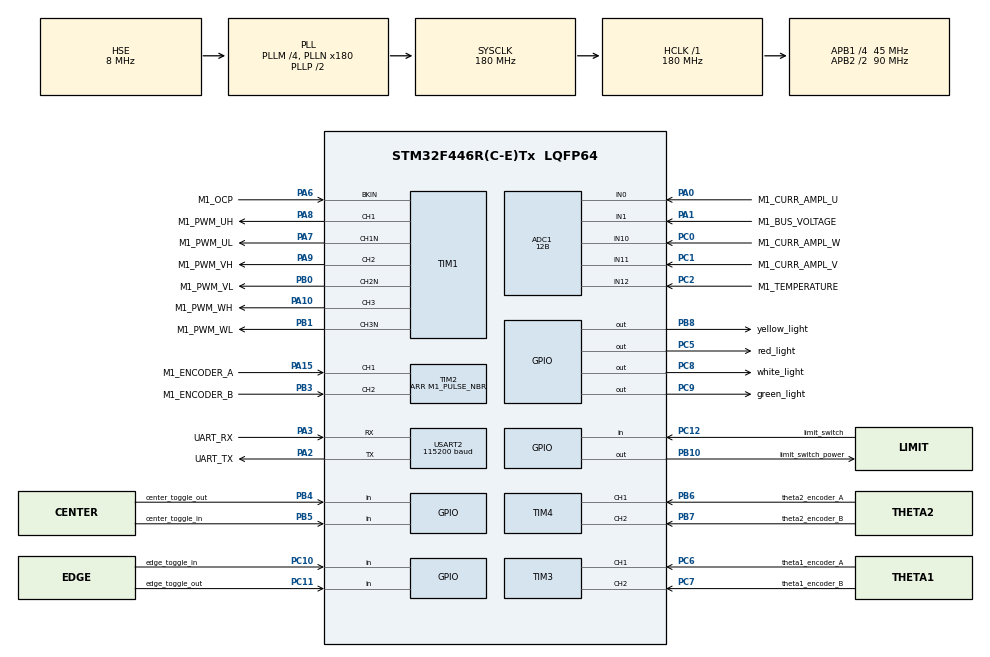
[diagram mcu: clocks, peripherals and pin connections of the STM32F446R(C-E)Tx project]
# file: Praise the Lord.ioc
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ADC1.Channel-1\#ChannelInjectedConversion=ADC_CHANNEL_0
ADC1.Channel-1\#ChannelRegularConversion=ADC_CHANNEL_1
ADC1.Channel-2\#ChannelInjectedConversion=ADC_CHANNEL_11
ADC1.Channel-2\#ChannelRegularConversion=ADC_CHANNEL_12
ADC1.Channel-3\#ChannelInjectedConversion=ADC_CHANNEL_10
ADC1.ClockPrescaler=ADC_CLOCK_SYNC_PCLK_DIV4
ADC1.ContinuousConvMode=DISABLE
ADC1.DMAContinuousRequests=DISABLE
ADC1.DataAlign=ADC_DATAALIGN_LEFT
ADC1.DiscontinuousConvMode=DISABLE
ADC1.EOCSelection=ADC_EOC_SINGLE_CONV
ADC1.EnableAnalogWatchDog=false
ADC1.EnableInjectedConversion=ENABLE
ADC1.EnableRegularConversion=ENABLE
ADC1.ExternalTrigConv=ADC_SOFTWARE_START
ADC1.ExternalTrigConvEdge=ADC_EXTERNALTRIGCONVEDGE_NONE
ADC1.ExternalTrigInjecConv=ADC_EXTERNALTRIGINJECCONV_T1_CC4
ADC1.ExternalTrigInjecConvEdge=ADC_EXTERNALTRIGINJECCONVEDGE_RISING
ADC1.InjNumberOfConversion=3
ADC1.InjectedConvMode=None
ADC1.InjectedOffset-1\#ChannelInjectedConversion=0
ADC1.InjectedOffset-2\#ChannelInjectedConversion=0
ADC1.InjectedOffset-3\#ChannelInjectedConversion=0
ADC1.InjectedRank-1\#ChannelInjectedConversion=1
ADC1.InjectedRank-2\#ChannelInjectedConversion=2
ADC1.InjectedRank-3\#ChannelInjectedConversion=3
ADC1.NbrOfConversion=2
ADC1.NbrOfConversionFlag=1
ADC1.Offset-1\#ChannelRegularConversion=0
ADC1.Offset-2\#ChannelRegularConversion=0
ADC1.OffsetNumber-1\#ChannelRegularConversion=ADC_OFFSET_NONE
ADC1.OffsetNumber-2\#ChannelRegularConversion=ADC_OFFSET_NONE
ADC1.Rank-1\#ChannelRegularConversion=1
ADC1.Rank-2\#ChannelRegularConversion=2
ADC1.Resolution=ADC_RESOLUTION_12B
ADC1.SamplingTime-1\#ChannelInjectedConversion=ADC_SAMPLETIME_15CYCLES
ADC1.SamplingTime-1\#ChannelRegularConversion=ADC_SAMPLETIME_28CYCLES
ADC1.SamplingTime-2\#ChannelInjectedConversion=ADC_SAMPLETIME_15CYCLES
ADC1.SamplingTime-2\#ChannelRegularConversion=ADC_SAMPLETIME_28CYCLES
ADC1.SamplingTime-3\#ChannelInjectedConversion=ADC_SAMPLETIME_15CYCLES
ADC1.ScanConvMode=ENABLE
ADC1.master=1
Dma.Request0=USART2_RX
Dma.Request1=USART2_TX
Dma.USART2_RX.0.Direction=DMA_PERIPH_TO_MEMORY
Dma.USART2_RX.0.FIFOMode=DMA_FIFOMODE_DISABLE
Dma.USART2_RX.0.Instance=DMA1_Stream5
Dma.USART2_RX.0.MemDataAlignment=DMA_MDATAALIGN_BYTE
Dma.USART2_RX.0.MemInc=DMA_MINC_ENABLE
Dma.USART2_RX.0.Mode=DMA_NORMAL
Dma.USART2_RX.0.PeriphDataAlignment=DMA_PDATAALIGN_BYTE
Dma.USART2_RX.0.PeriphInc=DMA_PINC_DISABLE
Dma.USART2_RX.0.Priority=DMA_PRIORITY_LOW
Dma.USART2_TX.1.Direction=DMA_MEMORY_TO_PERIPH
Dma.USART2_TX.1.FIFOMode=DMA_FIFOMODE_DISABLE
Dma.USART2_TX.1.Instance=DMA1_Stream6
Dma.USART2_TX.1.MemDataAlignment=DMA_MDATAALIGN_BYTE
Dma.USART2_TX.1.MemInc=DMA_MINC_ENABLE
Dma.USART2_TX.1.Mode=DMA_NORMAL
Dma.USART2_TX.1.PeriphDataAlignment=DMA_PDATAALIGN_BYTE
Dma.USART2_TX.1.PeriphInc=DMA_PINC_DISABLE
Dma.USART2_TX.1.Priority=DMA_PRIORITY_LOW
ExtraMW=MotorControl
ExtraMW.MotorControl.Config=MotorControl
ExtraMW.MotorControl.Mode=MotorControl
ExtraMW.MotorControl.Root=MCSDK_v6.3.2-Full/MotorControl
ExtraMW.MotorControl.Template=templates
Mcu.Family=STM32F4
Mcu.Name=STM32F446R(C-E)Tx
Mcu.Package=LQFP64
MotorControl.ADC_AHBPERIPH=RCC_AHBPeriph_ADC1
MotorControl.ADC_CLOCK_WB_DIV=1
MotorControl.ADC_PERIPH=ADC1
MotorControl.ADC_REFERENCE_VOLTAGE=3.3
MotorControl.BOARD=NUCLEO-F446RE
MotorControl.BUS_VOLTAGE_READING=true
MotorControl.CCMRAM_ENABLED=false
MotorControl.CLOCK_FREQUENCY=CPU_CLK_180_MHZ
MotorControl.CLOCK_SOURCE=EXTERNAL
MotorControl.CPU_CLK_180_MHZ=true
MotorControl.CTLBOARD_NAME=NUCLEO-F446RE
MotorControl.CUBE_MX_VER=6.13.0
MotorControl.CURRENT_READING_TOPOLOGY=THREE_SHUNT
MotorControl.CURR_SAMPLING_TIME=15
MotorControl.DBG_MCU_LOAD_MEASURE=false
MotorControl.DEBUG_DAC_FUNCTIONALITY_EN=false
MotorControl.DRIVES_NUMBER_SELECTION=SINGLEDRIVE
MotorControl.DRIVE_NUMBER=1
MotorControl.DRIVE_TYPE=FOC
MotorControl.EMERGENCY_STOP_GPIO_PIN=LL_GPIO_PIN_6
MotorControl.EMERGENCY_STOP_GPIO_PORT=GPIOA
MotorControl.ENCODER=true
MotorControl.ENCODER_AVAILABLE=true
MotorControl.ENCODER_PPR=2048
MotorControl.ENC_A_GPIO_PIN=LL_GPIO_PIN_15
MotorControl.ENC_A_GPIO_PORT=GPIOA
MotorControl.ENC_B_GPIO_PIN=LL_GPIO_PIN_3
MotorControl.ENC_B_GPIO_PORT=GPIOB
MotorControl.ENC_ICx_FILTER=126
MotorControl.ENC_INVERT_SPEED=false
MotorControl.ENC_TIMER_SELECTION=ENC_TIM2
MotorControl.ENC_USE_CH3=false
MotorControl.EXT_CLK_8_MHZ=true
MotorControl.EXT_CLOCK_FREQUENCY=EXT_CLK_8_MHZ
MotorControl.FEEDBACK_NET_FILTERING=false
MotorControl.FLASH_SIZE=512
MotorControl.HALL_SENSORS_AVAILABLE=false
MotorControl.HIGH_SIDE_IDLE_STATE=false
MotorControl.HWV_CS=ThreeShunt_AmplifiedCurrents
MotorControl.HWV_OCP=OnPowerStageOCP
MotorControl.HWV_PWM=DrivingHighAndLowSides
MotorControl.HW_COMPLEMENTED_LOW_SIDE=false
MotorControl.HW_DEAD_TIME_NS=1000
MotorControl.IPs=NVIC,RCC,SYS,MotorControl,ADC1,TIM1,TIM2,USART2,DMA
MotorControl.LOW_MEMORY_FOOTPRINT_REG=false
MotorControl.LOW_SIDE_IDLE_STATE=false
MotorControl.LOW_SIDE_SIGNALS_ENABLING=LS_PWM_TIMER
MotorControl.M1_ALIGNMENT_ANGLE_DEG=90
MotorControl.M1_ALIGNMENT_DURATION=700
MotorControl.M1_AMPLIFICATION_GAIN=5.18
MotorControl.M1_ANGC={0,0,0,0,0,0,0,0}
MotorControl.M1_AUXILIARY_SPEED_SENSOR=NONE
MotorControl.M1_BOARD_MAX_CURRENT=19
MotorControl.M1_BUS_VOLTAGE_READING=true
MotorControl.M1_COMMUTATION_STEP_TIME_BUF_SIZE=12
MotorControl.M1_CONSTANT1_D=21764
MotorControl.M1_CONSTANT1_Q=21764
MotorControl.M1_CONSTANT2_QD=57888
MotorControl.M1_CS_ADC_NUM=1
MotorControl.M1_CS_ADC_PHASE_SHARED=NONE
MotorControl.M1_CS_ADC_U=ADC1
MotorControl.M1_CS_ADC_V=ADC1
MotorControl.M1_CS_ADC_W=ADC1
MotorControl.M1_CS_CHANNEL_U=0
MotorControl.M1_CS_CHANNEL_V=11
MotorControl.M1_CS_CHANNEL_W=10
MotorControl.M1_CURRENT_AMPLIFICATION_TOPO=EXTERNAL
MotorControl.M1_CURRENT_SENSING_TOPO=THREE_SHUNT
MotorControl.M1_CURR_SAMPLING_TIME=15
MotorControl.M1_DBG_OPEN_LOOP_ENABLE=false
MotorControl.M1_DC_CURRENT_RS_MEAS=19
MotorControl.M1_DEFAULT_CONTROL_MODE=STC_TORQUE_MODE
MotorControl.M1_DEFAULT_FLUX_COMPONENT=0
MotorControl.M1_DEFAULT_TARGET_SPEED_RPM=2340
MotorControl.M1_DEFAULT_TORQUE_COMPONENT=0.0001
MotorControl.M1_DISCONTINUOUS_PWM=false
MotorControl.M1_DP_TOPOLOGY=NONE
MotorControl.M1_DRIVE_TYPE=FOC
MotorControl.M1_ENCODER_PPR=2048
MotorControl.M1_ENC_AVERAGING_FIFO_DEPTH=16
MotorControl.M1_ENC_A_GPIO_PIN=LL_GPIO_PIN_15
MotorControl.M1_ENC_A_GPIO_PORT=GPIOA
MotorControl.M1_ENC_B_GPIO_PIN=LL_GPIO_PIN_3
MotorControl.M1_ENC_B_GPIO_PORT=GPIOB
MotorControl.M1_ENC_ICx_FILTER=126
MotorControl.M1_ENC_TIMER_IRQ=TIM2
MotorControl.M1_ENC_TIMER_SELECTION=ENC_TIM2
MotorControl.M1_ENC_USE_CH3=false
MotorControl.M1_FEED_FORWARD_CURRENT_REG_ENABLING=false
MotorControl.M1_FINAL_I_ALIGNMENT=19
MotorControl.M1_FLUX_WEAKENING_ENABLING=false
MotorControl.M1_FW_KIDIV=32768
MotorControl.M1_FW_KI_GAIN=5000
MotorControl.M1_FW_KPDIV=32768
MotorControl.M1_FW_KP_GAIN=3000
MotorControl.M1_FW_VOLTAGE_REF=985
MotorControl.M1_HALL_PHASE_SHIFT=300
MotorControl.M1_HALL_SENSORS_PLACEMENT=DEGREES_120
MotorControl.M1_HIGH_SIDE_IDLE_STATE=false
MotorControl.M1_HW_DEAD_TIME_NS=1000
MotorControl.M1_ICL_ENABLED=false
MotorControl.M1_ID_DEMAG=-19
MotorControl.M1_IQMAX=19
MotorControl.M1_LDLQ_RATIO=1.000
MotorControl.M1_LOW_SIDE_IDLE_STATE=false
MotorControl.M1_LOW_SIDE_SIGNALS_ENABLING=LS_PWM_TIMER
MotorControl.M1_LS=0.000021
MotorControl.M1_MAX_APPLICATION_SPEED=6500
MotorControl.M1_MAX_MODULATION_INDEX=97
MotorControl.M1_MIN_APPLICATION_SPEED=0
MotorControl.M1_MOTOR_MAX_SPEED_RPM=6500
MotorControl.M1_MOTOR_NAME=Jay's Motor
MotorControl.M1_MOTOR_RATED_FLUX=0.089406376
MotorControl.M1_MOTOR_VOLTAGE_CONSTANT=7.3
MotorControl.M1_MTPA_ENABLING=false
MotorControl.M1_NOMINAL_BUS_VOLTAGE_V=48
MotorControl.M1_NOMINAL_CURRENT=19
MotorControl.M1_OCP_BKIN_FILTER=3
MotorControl.M1_OCP_BKIN_MODE=EXT_MODE
MotorControl.M1_OCP_BKIN_POLARITY=EMSTOP_ACTIVE_LOW
MotorControl.M1_OCP_DESTINATION=TIM_BKIN
MotorControl.M1_OCP_TOPOLOGY=EXTERNAL
MotorControl.M1_OFST={0,0,0,0,0,0,0,0}
MotorControl.M1_ON_OVER_VOLTAGE=TURN_OFF_PWM
MotorControl.M1_OVERMODULATION=false
MotorControl.M1_OVP_THRESHOLD_HIGH=48
MotorControl.M1_OV_TEMPERATURE_HYSTERESIS_C=10
MotorControl.M1_OV_TEMPERATURE_PROT_ENABLING=true
MotorControl.M1_OV_TEMPERATURE_THRESHOLD_C=90
MotorControl.M1_OV_VOLTAGE_PROT_ENABLING=true
MotorControl.M1_OV_VOLTAGE_THRESHOLD_V=48
MotorControl.M1_PID_FLUX_KD_DEFAULT=100
MotorControl.M1_PID_FLUX_KI_DEFAULT=2022
MotorControl.M1_PID_FLUX_KP_DEFAULT=2739
MotorControl.M1_PID_SPEED_KD_DEFAULT=0
MotorControl.M1_PID_SPEED_KI_DEFAULT=292
MotorControl.M1_PID_SPEED_KP_DEFAULT=3257
MotorControl.M1_PID_TORQUE_KD_DEFAULT=100
MotorControl.M1_PID_TORQUE_KI_DEFAULT=2022
MotorControl.M1_PID_TORQUE_KP_DEFAULT=2739
MotorControl.M1_POLE_PAIR_NUM=4
MotorControl.M1_POSITION_CTRL_ENABLING=false
MotorControl.M1_POTENTIOMETER_ENABLE=false
MotorControl.M1_POWERBOARD_NAME=X-NUCLEO-IHM08M1
MotorControl.M1_PWM_CHARGE_BOOT_CAP_DUTY_CYCLES=0.000
MotorControl.M1_PWM_CHARGE_BOOT_CAP_MS=10
MotorControl.M1_PWM_DRIVER_PN=L6398
MotorControl.M1_PWM_FREQUENCY=20000
MotorControl.M1_PWM_TIMER_BRK_IRQ=TIM1_BRK_TIM9
MotorControl.M1_PWM_TIMER_SELECTION=PWM_TIM1
MotorControl.M1_PWM_TIMER_UP_IRQ=TIM1_UP_TIM10
MotorControl.M1_REGULATION_EXECUTION_RATE=1
MotorControl.M1_RS=0.31
MotorControl.M1_RSHUNT=0.01
MotorControl.M1_SEGDIV=0
MotorControl.M1_SHARED_SIGNAL_ENABLE=false
MotorControl.M1_SPD_DIFFERENTIAL_TERM_ENABLING=false
MotorControl.M1_SPEED_LOOP_FREQUENCY_HZ=1000
MotorControl.M1_SPEED_SENSOR=QUAD_ENCODER
MotorControl.M1_SP_KDDIV=16
MotorControl.M1_SP_KIDIV=16384
MotorControl.M1_SP_KPDIV=512
MotorControl.M1_SS_MEAS_ERRORS_BEFORE_FAULTS=3
MotorControl.M1_SW_DEADTIME_NS=850
MotorControl.M1_T0_C=25
MotorControl.M1_TEMPERATURE_READING=true
MotorControl.M1_TEMP_ADC_SAMPLING_TIME=28
MotorControl.M1_TEMP_FDBK_ADC=ADC1
MotorControl.M1_TEMP_FDBK_CHANNEL=ADC_CHANNEL_12
MotorControl.M1_TF_KDDIV=8192
MotorControl.M1_TF_KIDIV=16384
MotorControl.M1_TF_KPDIV=16384
MotorControl.M1_TNOISE_NS=1000
MotorControl.M1_TRISE_NS=1000
MotorControl.M1_T_MAX=110
MotorControl.M1_UD_VOLTAGE_THRESHOLD_V=10
MotorControl.M1_USE_INTERNAL_OPAMP=false
MotorControl.M1_UV_VOLTAGE_PROT_ENABLING=true
MotorControl.M1_V0_V=1.055
MotorControl.M1_VBUS_ADC=ADC1
MotorControl.M1_VBUS_ADC_SAMPLING_TIME=28
MotorControl.M1_VBUS_CHANNEL=ADC_CHANNEL_1
MotorControl.M1_VBUS_PARTITIONING_FACTOR=0.052164840897235255
MotorControl.M1_dV_dT=0.023
MotorControl.MAX_READABLE_CURRENT=31.845
MotorControl.MCPA_OVER_UART_A_STREAM=10
MotorControl.MCP_ASPEP_OVER_UART=true
MotorControl.MCP_ASYNC_EN=true
MotorControl.MCP_ASYNC_OVER_ASPEP_EN=true
MotorControl.MCP_ASYNC_OVER_UART_A_EN=true
MotorControl.MCP_DMACH_RX_UART_A=5
MotorControl.MCP_DMACH_TX_UART_A=6
MotorControl.MCP_DMA_RX_UART_A=DMA1
MotorControl.MCP_DMA_TX_UART_A=DMA1
MotorControl.MCP_EN=true
MotorControl.MCP_IRQ_HANDLER_DMA_RX_UART_A=DMA1_Stream5_IRQHandler
MotorControl.MCP_IRQ_HANDLER_UART_A=USART2_IRQHandler
MotorControl.MCP_OVER_ASPEP_EN=true
MotorControl.MCP_OVER_STLNK_EN=false
MotorControl.MCP_OVER_UART_A_EN=true
MotorControl.MCP_OVER_UART_B_EN=false
MotorControl.MCP_RX_SYNC_PAYLOAD_MAX=128
MotorControl.MCP_TX_ASYNC_PAYLOAD_MAX_UART_A=2048
MotorControl.MCP_TX_SYNC_PAYLOAD_MAX=128
MotorControl.MCU=STM32F446RE
MotorControl.MCU_FAMILY=STM32F4
MotorControl.MCU_LINE=STM32F446
MotorControl.MCU_NAME=STM32F446R(C-E)Tx
MotorControl.MCU_PACKAGE=LQFP64
MotorControl.MCU_TYPE=STM32F446RE
MotorControl.MCU_USERNAME=STM32F446RETx
MotorControl.MC_WORKBENCH_VERSION=6.3.2
MotorControl.MOTOR_PROFILER=false
MotorControl.MOTOR_TYPE=PMSM
MotorControl.ON_OVER_VOLTAGE=TURN_OFF_PWM
MotorControl.OV_TEMPERATURE_PROT_ENABLING=true
MotorControl.OV_VOLTAGE_PROT_ENABLING=true
MotorControl.PHASE_UH_GPIO_PIN=LL_GPIO_PIN_8
MotorControl.PHASE_UH_GPIO_PORT=GPIOA
MotorControl.PHASE_UH_POLARITY=H_ACTIVE_HIGH
MotorControl.PHASE_UL_GPIO_PIN=LL_GPIO_PIN_7
MotorControl.PHASE_UL_GPIO_PORT=GPIOA
MotorControl.PHASE_UL_POLARITY=L_ACTIVE_LOW
MotorControl.PHASE_U_CURR_ADC=ADC1
MotorControl.PHASE_U_CURR_CHANNEL=ADC_CHANNEL_0
MotorControl.PHASE_U_GPIO_PIN=LL_GPIO_PIN_0
MotorControl.PHASE_U_GPIO_PORT=GPIOA
MotorControl.PHASE_U_PWM_CHANNEL=TIM_Channel_1
MotorControl.PHASE_VH_GPIO_PIN=LL_GPIO_PIN_9
MotorControl.PHASE_VH_GPIO_PORT=GPIOA
MotorControl.PHASE_VH_POLARITY=H_ACTIVE_HIGH
MotorControl.PHASE_VL_GPIO_PIN=LL_GPIO_PIN_0
MotorControl.PHASE_VL_GPIO_PORT=GPIOB
MotorControl.PHASE_VL_POLARITY=L_ACTIVE_LOW
MotorControl.PHASE_V_CURR_ADC=ADC1
MotorControl.PHASE_V_CURR_CHANNEL=ADC_CHANNEL_11
MotorControl.PHASE_V_GPIO_PIN=LL_GPIO_PIN_1
MotorControl.PHASE_V_GPIO_PORT=GPIOC
MotorControl.PHASE_V_PWM_CHANNEL=TIM_Channel_2
MotorControl.PHASE_WH_GPIO_PIN=LL_GPIO_PIN_10
MotorControl.PHASE_WH_GPIO_PORT=GPIOA
MotorControl.PHASE_WH_POLARITY=H_ACTIVE_HIGH
MotorControl.PHASE_WL_GPIO_PIN=LL_GPIO_PIN_1
MotorControl.PHASE_WL_GPIO_PORT=GPIOB
MotorControl.PHASE_WL_POLARITY=L_ACTIVE_LOW
MotorControl.PHASE_W_CURR_ADC=ADC1
MotorControl.PHASE_W_CURR_CHANNEL=ADC_CHANNEL_10
MotorControl.PHASE_W_GPIO_PIN=LL_GPIO_PIN_0
MotorControl.PHASE_W_GPIO_PORT=GPIOC
MotorControl.PHASE_W_PWM_CHANNEL=TIM_Channel_3
MotorControl.POTENTIOMETER_READING=false
MotorControl.PWM_FREQUENCY=20000
MotorControl.PWM_TIMER_SELECTION=PWM_TIM1
MotorControl.REGULATION_EXECUTION_RATE=1
MotorControl.RTOS=NONE
MotorControl.R_BRAKE_SWITCH_OFF_THRES_V=38
MotorControl.SINGLEDRIVE=true
MotorControl.SPD_DIFFERENTIAL_TERM_ENABLING=false
MotorControl.SPEED_SENSOR_SELECTION=ENCODER
MotorControl.START_STOP_BTN=false
MotorControl.STM32F446RE=true
MotorControl.SW_DEADTIME_NS=850
MotorControl.TEMPERATURE_READING=true
MotorControl.TEMP_ADC_SAMPLING_TIME=28
MotorControl.TEMP_FDBK_ADC=ADC1
MotorControl.TEMP_FDBK_CHANNEL=ADC_CHANNEL_12
MotorControl.TEMP_FDBK_GPIO_PIN=LL_GPIO_PIN_2
MotorControl.TEMP_FDBK_GPIO_PORT=GPIOC
MotorControl.TFDIFFERENTIAL_TERM_ENABLING=false
MotorControl.THREE_SHUNT=true
MotorControl.TRISE_NS=1000
MotorControl.USART_RX_GPIO_PIN=LL_GPIO_PIN_3
MotorControl.USART_RX_GPIO_PORT=GPIOA
MotorControl.USART_SELECTION=USE_USART2
MotorControl.USART_SELECTION_A=USART2
MotorControl.USART_SPEED=115200
MotorControl.USART_TX_GPIO_PIN=LL_GPIO_PIN_2
MotorControl.USART_TX_GPIO_PORT=GPIOA
MotorControl.USE_3OPAMPS=false
MotorControl.USE_INTERNAL_OPAMP=false
MotorControl.UV_VOLTAGE_PROT_ENABLING=true
MotorControl.VBUS_ADC=ADC1
MotorControl.VBUS_ADC_SAMPLING_TIME=28
MotorControl.VBUS_CHANNEL=ADC_CHANNEL_1
MotorControl.VBUS_GPIO_PIN=LL_GPIO_PIN_1
MotorControl.VBUS_GPIO_PORT=GPIOA
MotorControl.WB_UI_CUTOFF_FREQUENCY=6000
MotorControl.WB_UI_ENCODER_HAS_INDEX_PIN=false
MotorControl.WB_UI_FLUX_TARGET=0
MotorControl.WB_UI_FRICTION=14
MotorControl.WB_UI_INERTIA=5
MotorControl.WB_UI_MAGNETIC_STRUCTURE=SM-PMSM
MotorControl.WB_UI_MAX_CURRENT=19
MotorControl.WB_UI_MAX_NOMINAL_DC_VOLTAGE=48
MotorControl.WB_UI_MAX_PWMFREQUENCY=100000
MotorControl.WB_UI_MOTOR_DESCRIPTION=brushless DC motor with encoder and Z Index
MotorControl.WB_UI_OCP_DISABLING_ENABLE=false
MotorControl.WB_UI_OCP_THRESHOLD=30
MotorControl.WB_UI_PW_BOARD_MAX_RATED_CURRENT=30
MotorControl.WB_UI_PW_BOARD_MAX_VOLTAGE=48
MotorControl.WB_UI_PW_BOARD_MIN_VOLTAGE=10
MotorControl.WB_UI_VPOL=1.71
MotorControl.WB_to_Mx_template_version=24-04-17
MotorControl.WB_to_Mx_version=6.2.3
NVIC.ADC_IRQn=true\:2\:0\:true\:true\:false\:3\:false\:true\:true
NVIC.DMA1_Stream5_IRQn=true\:3\:0\:true\:true\:false\:2\:true\:true\:true
NVIC.PriorityGroup=NVIC_PRIORITYGROUP_3
NVIC.TIM1_BRK_TIM9_IRQn=true\:4\:1\:false\:true\:false\:5\:true\:true\:true
NVIC.TIM1_TRG_COM_TIM11_IRQn=true\:0\:0\:false\:false\:true\:true\:true\:true
NVIC.TIM1_UP_TIM10_IRQn=true\:0\:0\:false\:true\:false\:4\:true\:true\:true
NVIC.TIM2_IRQn=true\:3\:0\:false\:true\:false\:6\:true\:true\:true
NVIC.TIM8_TRG_COM_TIM14_IRQn=true\:0\:0\:false\:false\:true\:true\:true\:true
NVIC.TIM8_UP_TIM13_IRQn=true\:0\:0\:false\:false\:true\:true\:true\:true
NVIC.USART2_IRQn=true\:3\:1\:true\:true\:false\:1\:true\:true\:true
PA0-WKUP.GPIO_Label=M1_CURR_AMPL_U
PA0-WKUP.Signal=ADCx_IN0
PA1.GPIO_Label=M1_BUS_VOLTAGE
PA1.Signal=ADCx_IN1
PA10.GPIO_Label=M1_PWM_WH
PA10.GPIO_PuPd=GPIO_PULLDOWN
PA10.GPIO_Speed=GPIO_SPEED_FREQ_HIGH
PA10.Signal=S_TIM1_CH3
PA15.GPIO_Label=M1_ENCODER_A
PA15.Signal=S_TIM2_CH1_ETR
PA2.GPIO_Label=UART_TX
PA2.GPIO_Mode=GPIO_MODE_AF_PP
PA2.GPIO_PuPd=GPIO_NOPULL
PA2.GPIO_Speed=GPIO_SPEED_FREQ_LOW
PA2.Mode=Asynchronous
PA2.Signal=USART2_TX
PA3.GPIO_Label=UART_RX
PA3.GPIO_Mode=GPIO_MODE_AF_PP
PA3.GPIO_PuPd=GPIO_NOPULL
PA3.GPIO_Speed=GPIO_SPEED_FREQ_LOW
PA3.Mode=Asynchronous
PA3.Signal=USART2_RX
PA6.GPIO_Label=M1_OCP
PA6.GPIO_PuPd=GPIO_PULLUP
PA6.Mode=Activate-Break-Input
PA6.Signal=TIM1_BKIN
PA7.GPIO_Label=M1_PWM_UL
PA7.GPIO_PuPd=GPIO_PULLUP
PA7.GPIO_Speed=GPIO_SPEED_FREQ_HIGH
PA7.Mode=PWM Generation1 CH1 CH1N
PA7.Signal=TIM1_CH1N
PA8.GPIO_Label=M1_PWM_UH
PA8.GPIO_PuPd=GPIO_PULLDOWN
PA8.GPIO_Speed=GPIO_SPEED_FREQ_HIGH
PA8.Signal=S_TIM1_CH1
PA9.GPIO_Label=M1_PWM_VH
PA9.GPIO_PuPd=GPIO_PULLDOWN
PA9.GPIO_Speed=GPIO_SPEED_FREQ_HIGH
PA9.Signal=S_TIM1_CH2
PB0.GPIO_Label=M1_PWM_VL
PB0.GPIO_PuPd=GPIO_PULLUP
PB0.GPIO_Speed=GPIO_SPEED_FREQ_HIGH
PB0.Mode=PWM Generation2 CH2 CH2N
PB0.Signal=TIM1_CH2N
PB1.GPIO_Label=M1_PWM_WL
PB1.GPIO_PuPd=GPIO_PULLUP
PB1.GPIO_Speed=GPIO_SPEED_FREQ_HIGH
PB1.Mode=PWM Generation3 CH3 CH3N
PB1.Signal=TIM1_CH3N
PB10.GPIO_Label=limit_switch_power
PB10.GPIO_ModeDefaultOutputPP=GPIO_MODE_OUTPUT_PP
PB10.GPIO_Speed=GPIO_SPEED_FREQ_VERY_HIGH
PB10.PinState=GPIO_PIN_SET
PB10.Signal=GPIO_Output
PB3.GPIO_Label=M1_ENCODER_B
PB3.Signal=S_TIM2_CH2
PB4.GPIO_Label=center_toggle_out
PB4.GPIO_PuPd=GPIO_PULLDOWN
PB4.Signal=GPIO_Input
PB5.GPIO_Label=center_toggle_in
PB5.GPIO_PuPd=GPIO_PULLDOWN
PB5.Signal=GPIO_Input
PB6.GPIO_Label=theta2_encoder_A
PB6.Signal=S_TIM4_CH1
PB7.GPIO_Label=theta2_encoder_B
PB7.Signal=S_TIM4_CH2
PB8.GPIO_Label=yellow_light
PB8.PinState=GPIO_PIN_SET
PB8.Signal=GPIO_Output
PC0.GPIO_Label=M1_CURR_AMPL_W
PC0.Signal=ADCx_IN10
PC1.GPIO_Label=M1_CURR_AMPL_V
PC1.Signal=ADCx_IN11
PC10.GPIO_Label=edge_toggle_in
PC10.GPIO_PuPd=GPIO_PULLDOWN
PC10.Signal=GPIO_Input
PC11.GPIO_Label=edge_toggle_out
PC11.GPIO_PuPd=GPIO_PULLDOWN
PC11.Signal=GPIO_Input
PC12.GPIO_Label=limit_switch
PC12.GPIO_PuPd=GPIO_PULLDOWN
PC12.Signal=GPIO_Input
PC2.GPIO_Label=M1_TEMPERATURE
PC2.Signal=ADCx_IN12
PC5.GPIO_Label=red_light
PC5.PinState=GPIO_PIN_SET
PC5.Signal=GPIO_Output
PC6.GPIO_Label=theta1_encoder_A
PC6.Signal=S_TIM3_CH1
PC7.GPIO_Label=theta1_encoder_B
PC7.Signal=S_TIM3_CH2
PC8.GPIO_Label=white_light
PC8.PinState=GPIO_PIN_SET
PC8.Signal=GPIO_Output
PC9.GPIO_Label=green_light
PC9.PinState=GPIO_PIN_SET
PC9.Signal=GPIO_Output
PH0-OSC_IN.Mode=HSE-External-Oscillator
PH0-OSC_IN.Signal=RCC_OSC_IN
PH1-OSC_OUT.Mode=HSE-External-Oscillator
PH1-OSC_OUT.Signal=RCC_OSC_OUT
ProjectManager.HeapSize=0x200
ProjectManager.StackSize=0x400
ProjectManager.TargetToolchain=STM32CubeIDE
RCC.AHBFreq_Value=180000000
RCC.APB1CLKDivider=RCC_HCLK_DIV4
RCC.APB1Freq_Value=45000000
RCC.APB1TimFreq_Value=90000000
RCC.APB2CLKDivider=RCC_HCLK_DIV2
RCC.APB2Freq_Value=90000000
RCC.APB2TimFreq_Value=180000000
RCC.CortexFreq_Value=180000000
RCC.HCLKFreq_Value=180000000
RCC.HSE_VALUE=8000000
RCC.PLLM=4
RCC.PLLN=180
RCC.PLLSourceVirtual=RCC_PLLSOURCE_HSE
RCC.PREFETCH_ENABLE=1
RCC.SYSCLKFreq_VALUE=180000000
RCC.SYSCLKSource=RCC_SYSCLKSOURCE_PLLCLK
RCC.USBFreq_Value=180000000
RCC.VCOOutputFreq_Value=360000000
SH.ADCx_IN0.0=ADC1_IN0,IN0
SH.ADCx_IN1.0=ADC1_IN1,IN1
SH.ADCx_IN10.0=ADC1_IN10,IN10
SH.ADCx_IN11.0=ADC1_IN11,IN11
SH.ADCx_IN12.0=ADC1_IN12,IN12
SH.S_TIM1_CH1.0=TIM1_CH1,PWM Generation1 CH1 CH1N
SH.S_TIM1_CH2.0=TIM1_CH2,PWM Generation2 CH2 CH2N
SH.S_TIM1_CH3.0=TIM1_CH3,PWM Generation3 CH3 CH3N
SH.S_TIM2_CH1_ETR.0=TIM2_CH1,Encoder_Interface
SH.S_TIM2_CH2.0=TIM2_CH2,Encoder_Interface
SH.S_TIM3_CH1.0=TIM3_CH1,Encoder_Interface
SH.S_TIM3_CH2.0=TIM3_CH2,Encoder_Interface
SH.S_TIM4_CH1.0=TIM4_CH1,Encoder_Interface
SH.S_TIM4_CH2.0=TIM4_CH2,Encoder_Interface
TIM1.AutoReloadPreload=TIM_AUTORELOAD_PRELOAD_DISABLE
TIM1.AutomaticOutput=TIM_AUTOMATICOUTPUT_DISABLE
TIM1.BreakPolarity=TIM_BREAKPOLARITY_LOW
TIM1.BreakState=TIM_BREAK_ENABLE
TIM1.Channel-PWM\ Generation1\ CH1\ CH1N=TIM_CHANNEL_1
TIM1.Channel-PWM\ Generation2\ CH2\ CH2N=TIM_CHANNEL_2
TIM1.Channel-PWM\ Generation3\ CH3\ CH3N=TIM_CHANNEL_3
TIM1.Channel-PWM\ Generation4\ No\ Output=TIM_CHANNEL_4
TIM1.ClearInputSource=TIM_CLEARINPUTSOURCE_NONE
TIM1.ClockDivision=TIM_CLOCKDIVISION_DIV2
TIM1.CounterMode=TIM_COUNTERMODE_CENTERALIGNED1
TIM1.DeadTime=((DEAD_TIME_COUNTS) / 2)
TIM1.LockLevel=TIM_LOCKLEVEL_OFF
TIM1.OC1Preload_PWM=ENABLE
TIM1.OC2Preload_PWM=ENABLE
TIM1.OC3Preload_PWM=ENABLE
TIM1.OC4Preload_PWM=ENABLE
TIM1.OCIdleState_1=TIM_OCIDLESTATE_RESET
TIM1.OCIdleState_2=TIM_OCIDLESTATE_RESET
TIM1.OCIdleState_3=TIM_OCIDLESTATE_RESET
TIM1.OCIdleState_4=TIM_OCIDLESTATE_RESET
TIM1.OCMode_PWM-PWM\ Generation1\ CH1\ CH1N=TIM_OCMODE_PWM1
TIM1.OCMode_PWM-PWM\ Generation2\ CH2\ CH2N=TIM_OCMODE_PWM1
TIM1.OCMode_PWM-PWM\ Generation3\ CH3\ CH3N=TIM_OCMODE_PWM1
TIM1.OCMode_PWM-PWM\ Generation4\ No\ Output=TIM_OCMODE_PWM2
TIM1.OCNIdleState_1=TIM_OCNIDLESTATE_SET
TIM1.OCNIdleState_2=TIM_OCNIDLESTATE_SET
TIM1.OCNIdleState_3=TIM_OCNIDLESTATE_SET
TIM1.OCNPolarity_1=TIM_OCNPOLARITY_LOW
TIM1.OCNPolarity_2=TIM_OCNPOLARITY_LOW
TIM1.OCNPolarity_3=TIM_OCNPOLARITY_LOW
TIM1.OCPolarity_1=TIM_OCPOLARITY_HIGH
TIM1.OCPolarity_2=TIM_OCPOLARITY_HIGH
TIM1.OCPolarity_3=TIM_OCPOLARITY_HIGH
TIM1.OCPolarity_4=TIM_OCPOLARITY_HIGH
TIM1.OffStateIDLEMode=TIM_OSSI_ENABLE
TIM1.OffStateRunMode=TIM_OSSR_ENABLE
TIM1.Period=((PWM_PERIOD_CYCLES) / 2)
TIM1.Prescaler=((TIM_CLOCK_DIVIDER) - 1)
TIM1.Pulse-PWM\ Generation1\ CH1\ CH1N=((PWM_PERIOD_CYCLES) / 4)
TIM1.Pulse-PWM\ Generation2\ CH2\ CH2N=((PWM_PERIOD_CYCLES) / 4)
TIM1.Pulse-PWM\ Generation3\ CH3\ CH3N=((PWM_PERIOD_CYCLES) / 4)
TIM1.Pulse-PWM\ Generation4\ No\ Output=(((PWM_PERIOD_CYCLES) / 2) - (HTMIN))
TIM1.RepetitionCounter=(REP_COUNTER)
TIM1.TIM_MasterOutputTrigger=TIM_TRGO_RESET
TIM1.TIM_MasterSlaveMode=TIM_MASTERSLAVEMODE_DISABLE
TIM11.AutoReloadPreload=TIM_AUTORELOAD_PRELOAD_ENABLE
TIM11.Period=20000-1
TIM11.Prescaler=180-1
TIM13.Period=10000-1
TIM13.Prescaler=90-1
TIM14.Period=1000-1
TIM14.Prescaler=90-1
TIM2.EncoderMode=TIM_ENCODERMODE_TI12
TIM2.IC1Filter=M1_ENC_IC_FILTER
TIM2.IC1Polarity=TIM_ICPOLARITY_RISING
TIM2.IC2Filter=M1_ENC_IC_FILTER
TIM2.IC2Polarity=TIM_ICPOLARITY_RISING
TIM2.Period=M1_PULSE_NBR
TIM3.AutoReloadPreload=TIM_AUTORELOAD_PRELOAD_ENABLE
TIM3.EncoderMode=TIM_ENCODERMODE_TI12
TIM4.AutoReloadPreload=TIM_AUTORELOAD_PRELOAD_ENABLE
TIM4.EncoderMode=TIM_ENCODERMODE_TI12
USART2.BaudRate=115200
USART2.VirtualMode=VM_ASYNC
USART2.VirtualMode-Asynchronous=VM_ASYNC
USART2.WordLength=WORDLENGTH_8B
VP_MotorControl_MC_ENABLED.Mode=Enabled
VP_TIM11_VS_ClockSourceINT.Mode=Enable_Timer
VP_TIM13_VS_ClockSourceINT.Mode=Enable_Timer
VP_TIM14_VS_ClockSourceINT.Mode=Enable_Timer
VP_TIM1_VS_no_output4.Mode=PWM Generation4 No Output
board=custom

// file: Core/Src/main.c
/* USER CODE BEGIN Header */
/**
  ******************************************************************************
  * @file           : main.c
  * @brief          : Main program body
  ******************************************************************************
  * @attention
  *
  * Copyright (c) 2025 STMicroelectronics.
  * All rights reserved.
  *
  * This software is licensed under terms that can be found in the LICENSE file
  * in the root directory of this software component.
  * If no LICENSE file comes with this software, it is provided AS-IS.
  *
  ******************************************************************************
  */
/* USER CODE END Header */
#include "main.h"

/* USER CODE BEGIN Includes */
#include "quad_encoder.h"
/* USER CODE END Includes */

/* USER CODE BEGIN PD */
#define NO_FAULTS   0x00
#define DURATION    0x01
#define OVER_VOLT   0x02
#define UNDER_VOLT  0x04
#define OVER_TEMP   0x08
#define START_UP    0x10
#define SPEED_FDBK  0x20
#define BREAK_IN    0x40
#define SW_ERROR    0x80

#define BUFFER_SIZE 300  // Storing 3 seconds of data at 100 Hz
#define SAMPLE_INTERVAL 1  // Take a sample every 1 index (every 10ms at 100 Hz)
#define NUM_SAMPLES 100  // 100 samples spread over 3 seconds
/* USER CODE END PD */

ADC_HandleTypeDef hadc1;

TIM_HandleTypeDef htim1;
TIM_HandleTypeDef htim2;
TIM_HandleTypeDef htim3;
TIM_HandleTypeDef htim4;
TIM_HandleTypeDef htim11;
TIM_HandleTypeDef htim13;
TIM_HandleTypeDef htim14;

UART_HandleTypeDef huart2;
DMA_HandleTypeDef hdma_usart2_rx;
DMA_HandleTypeDef hdma_usart2_tx;

/* USER CODE BEGIN PV */
encoder_instance theta1_encoder;
encoder_instance theta2_encoder;
encoder_instance x_encoder;

float theta1; 		//Theta1 Position (rad), 0 = up. CW is Positive
float theta1_dot;				//Theta1 Velocity (rad/s), CW is Positive
float old_theta1 = 0;
uint16_t theta1_timer_counter;	//Clock for encoder

float theta2; 				//Theta2 Position (rad), 0 = in line with theta1. CW is Positive
float theta2_dot;				//Theta2 Velocity (rad/s), CW is Positive
float old_theta2 = 0;
uint16_t theta2_timer_counter;	//Clock for encoder

float x = 0;					//Cart Position (m), 0 = center track. Right is Positive
float x_dot;					//Cart Velocity (m/s), Right is Positive
float old_x = 0;
uint16_t x_timer_counter;		//Clock for encoder

float u;						//Control Input 	(Newtons)
int torque_limit = 40;			//Max Torque (Newtons)
float friction_offsets = 4;
float temp_u;
float natural_u;
float catch_window1 = .5;
float catch_window2 = .5;
float soft_limit_length = .8;	//Max distance from center
float speed_limit = 100;

float x_offset = 0;
float theta1_offset = 0; 		//Offsets to make encoders read zero
float theta2_offset = 0;		//Offsets to make encoders read zero
float x_buffer;
float theta1_buffer;
float theta2_buffer;
float theta1_drift = 0;
float theta2_drift = 0;

// Matrix K (1theta2_dot)
float K[6] = {-100.f, 1549.f, -2720.f, -173.6f, -26.36f, -465.f};

//Motor Variables
double current_constant = 0.265882353; //Amps/N
double current_requested = 0;
double radius = .02239;

double x_homing_offset;			//Used for homing sequence with limit switches
float elapsed_time = 0;			//Time in seconds
float swingup_time = 0;
float swingup_time_datum;
float tracking_time = 0;		//Time the system has been actively tracking in seconsd
int control_mode = 0;			//Set system control. 0 is initialization
uint16_t fault_code;
const char* fault_name;

bool actively_tracking = false;		//Keeps track of if the motor is actively tracking
bool actively_swinging_up = false;	//Keeps track of if the motor is actively swinging up
bool motor_enabled = false; 		//Motor safety switch. true means enabled
bool limit_switch_open;				//Disable Motor if limit switch is hit
bool motor_temp_high;				//Disable Motor if it gets too hot
bool soft_limits_breached;			//Disable control if outside of bounds
bool speed_limit_breached;			//Disable control if going too fast
bool catch_window_active;			//Enable control if in window

bool limit_switch_open_flag;		//Disable Motor if limit switch is hit
bool motor_temp_high_flag;			//Disable Motor if temp got too high
bool soft_limits_breached_flag;		//Disable control if outside of bounds
bool speed_limit_breached_flag;		//Disable control if going too fast
bool catch_window_active_flag;		//Enable control if in window

bool test_motor_init;
bool red_light_on;				//Indicates Red Light On
bool yellow_light_on;			//Indicates Yellow Light On
bool green_light_on;			//Indicates Green Light On
bool white_light_on;			//Indicates White Light On

int center_toggle;				//Stores Position of Center Toggle Switch
int edge_toggle;				//Stores Position of Outer Toggle Switch
int state_machine;

float motor_temp;

float velocity_swing_up_profile[][2] = {
	{ 0.001, 0 },
    { 0.141414, 3.143556 },
    { 0.161616, 3.184708 },
    { 0.363636, 0.521649 },
    { 0.666667, 0.043843 },
    { 0.747475, -0.201979 },
    { 1.010101, -4.477034 },
    { 1.393939, 2.359946 },
    { 1.838384, -0.432700 },
    { 1.979798, 0.000000 }
};

float force_swing_up_profile[][2] = {
    { 0.020202, 23.999787 },
    { 0.161616, 7.042774 },
    { 0.181818, -12.394399 },
    { 0.383838, -1.030226 },
    { 0.686869, -5.944503 },
    { 0.767677, -23.989512 },
    { 1.030303, 21.953005 },
    { 1.414141, -6.206167 },
    { 1.858586, 2.846756 }
};

float programed_speed;
float programed_ramp;
float programed_torque;
int counter_i;

MCI_State_t motor_state;

// Circular buffer structure
typedef struct {
    float data[BUFFER_SIZE];
    int index;
    int count;
} CircularBuffer;

// Global buffer instances for drift data
CircularBuffer drift_buffer1;
CircularBuffer drift_buffer2;
volatile uint32_t sample_counter = 0;

/* USER CODE END PV */

void SystemClock_Config(void);
static void MX_GPIO_Init(void);
static void MX_DMA_Init(void);
static void MX_ADC1_Init(void);
static void MX_TIM1_Init(void);
static void MX_TIM2_Init(void);
static void MX_USART2_UART_Init(void);
static void MX_TIM3_Init(void);
static void MX_TIM4_Init(void);
static void MX_TIM11_Init(void);
static void MX_TIM13_Init(void);
static void MX_TIM14_Init(void);
static void MX_NVIC_Init(void);
/* USER CODE BEGIN PFP */

//void update_buffer(CircularBuffer *buffer, float new_value);
//float compute_average(const CircularBuffer *buffer);
float get_rpm(float requested_speed);
bool check_limit_switch_open();
void drive_motor();

/* USER CODE END PFP */

/* USER CODE BEGIN 0 */
void HAL_TIM_PeriodElapsedCallback(TIM_HandleTypeDef *htim)
{
  /* USER CODE BEGIN Callback 0 */

//High Speed Tasks - System Monitoring and Open Loop Swing Up Response
	if (htim == &htim14) {

//System Monitoring
		x_timer_counter = __HAL_TIM_GET_COUNTER(&htim2);
		update_encoder(&x_encoder, &htim2);
		x = x_encoder.position * radius * 3.141 / (4*2048) + x_offset; //Ticks to m;
		x_buffer = x_encoder.position * radius * 3.141 / (4*2048);

		theta1_timer_counter = __HAL_TIM_GET_COUNTER(&htim3);
		update_encoder(&theta1_encoder, &htim3);
		theta1 = -1* theta1_encoder.position * 6.28318/(4*2048) + 3.14159 + theta1_offset - theta1_drift; //Ticks to radians
		theta1_buffer = -1* theta1_encoder.position * 6.28318/(4*2048) + 3.14159;

		theta2_timer_counter = __HAL_TIM_GET_COUNTER(&htim4);
		update_encoder(&theta2_encoder, &htim4);
		theta2 = theta1 + theta2_encoder.position * 6.28318/(4*2048) + theta2_offset - theta2_drift; //Ticks to Radians
		theta2_buffer = theta1 + theta2_encoder.position * 6.28318/(4*2048);

	    x_dot = (x - old_x) / .001;
	    old_x = x;

		elapsed_time = elapsed_time + .001;

		if(state_machine == 5){
			drive_motor();
		}
	}

//Low speed interrupts - 100 Hz
	if (htim == &htim13) {

////Angular Drift Compensation
//		if(tracking_time > 3){
//			update_buffer(&drift_buffer1, theta1);
//			update_buffer(&drift_buffer2, theta2);
//			sample_counter++;
//
//
//// Re-Compute average every 1 second (100 samples at 100Hz)
//			if (sample_counter >= 100) {
//				theta1_drift = compute_average(&drift_buffer1);
//				theta2_drift = compute_average(&drift_buffer2);
//
//				sample_counter = 0;  // Reset counter
//			}
//		}
	}

//Very Low speed interrupts - 50 Hz
	if (htim == &htim11) {
			static float theta1_dot_old;
			static float theta1_dot_new;
			static float theta2_dot_old;
			static float theta2_dot_new;

		//System Monitoring for Angular Speeds
			theta1_dot_new = (theta1 - old_theta1) / .02;
			theta2_dot_new = (theta2 - old_theta2) / .02;
			theta1_dot = theta1_dot_old * .4 + theta1_dot_new *.6;
			theta2_dot = theta2_dot_old * .4 + theta2_dot_new *.6;
			old_theta1 = theta1;
			old_theta2 = theta2;
			theta1_dot_old = theta1_dot;
			theta2_dot_old = theta2_dot;
	}

  /* USER CODE END Callback 0 */
  if (htim->Instance == TIM6) {
    HAL_IncTick();
  }
  /* USER CODE BEGIN Callback 1 */

  /* USER CODE END Callback 1 */
}

//void init_buffer(CircularBuffer *buffer) {
//    buffer->index = 0;
//    buffer->count = 0;
//}

// Function to store new data in the circular buffer
//void update_buffer(CircularBuffer *buffer, float new_value) {
//    buffer->data[buffer->index] = new_value;
//    buffer->index = (buffer->index + 1) % BUFFER_SIZE;
//    if (buffer->count < BUFFER_SIZE) {
//        buffer->count++;
//    }
//}
//
//// Function to compute the average using 100 samples spaced 10ms apart over 3 seconds
//float compute_average(const CircularBuffer *buffer) {
//    float sum = 0.0;
//    int start = (buffer->index - NUM_SAMPLES + BUFFER_SIZE) % BUFFER_SIZE;
//
//    for (int i = 0; i < NUM_SAMPLES; i++) {
//        sum += buffer->data[(start + i) % BUFFER_SIZE];
//    }
//
//    return sum / NUM_SAMPLES;
//}

float get_u_value(float x1, float x2, float x3, float x4, float x5, float x6){
	temp_u = x1*K[0] + x2*K[1] + x3*K[2] + x4*K[3] + x5*K[4] + x6*K[5]; 	//Computes u in Newtons
	natural_u = temp_u;
	if(x_dot > 0){
		temp_u = temp_u + friction_offsets; 	//add a bit to offset friction forces
	}

	if(x_dot < 0){
		temp_u = temp_u - friction_offsets;		//add a bit to offset friction forces
	}

  //Torque Limit to keep thing safe
	if(temp_u < -1*torque_limit){
		  temp_u = -1*torque_limit;
		  u = temp_u;
	  }
	else if(temp_u > torque_limit){
		  temp_u = torque_limit;
		  u = temp_u;
	  }
	else{
		u = temp_u;
	}
return u;
}

void speed_swing_up(){
	// Swing-up parameters
	static int current_index = 0;
	static int current_ramp_called = 0;
	static float last_ramp_start_time = 0; // Track when the last ramp started

	// Reset everything if swing-up just started
	if (swingup_time == 0) {
		current_index = 0;
		current_ramp_called = 0;
		last_ramp_start_time = 0;
		MC_StartMotor1();
	}

	if(swingup_time == 0){
		swingup_time_datum = elapsed_time;
	}
	actively_swinging_up = true;
	swingup_time = .00001 + elapsed_time - swingup_time_datum;

	if (current_index < (sizeof(velocity_swing_up_profile) / sizeof(velocity_swing_up_profile[0])) - 1) {

		float current_time = velocity_swing_up_profile[current_index][0];
		float next_time = velocity_swing_up_profile[current_index + 1][0];
		float next_speed = velocity_swing_up_profile[current_index + 1][1];

		// If we're in the correct time range
		if (swingup_time >= current_time && swingup_time < next_time) {
			if (current_ramp_called == 0) {
				float ramp_time = next_time - current_time;
				programed_speed = next_speed;
				programed_ramp = ramp_time;

				// Call speed ramp function
				MC_ProgramSpeedRampMotor1_F(get_rpm(programed_speed), programed_ramp);

				current_ramp_called = 1;  // Mark ramp as called
				last_ramp_start_time = swingup_time; // Track ramp start
			}
		}

		// Check if the ramp duration has passed, then move to the next index
		if (current_ramp_called == 1 && (swingup_time - last_ramp_start_time) >= (next_time - current_time)) {
			current_index++;
			current_ramp_called = 0; // Allow the next ramp to be called
		}
	}
}

void force_swing_up() {
	// Swing-up parameters
	static int current_index = 0;
	static int current_ramp_called = 0;
	static float last_ramp_start_time = 0; // Track when the last ramp started

	// Reset everything if swing-up just started
	if (swingup_time == 0) {
		current_index = 0;
		current_ramp_called = 0;
		last_ramp_start_time = 0;
		MC_StartMotor1();
	}

	if (swingup_time == 0) {
		swingup_time_datum = elapsed_time;
	}
	actively_swinging_up = 1;
	swingup_time = 0.00001f + elapsed_time - swingup_time_datum;

	if (current_index < (sizeof(force_swing_up_profile) / sizeof(force_swing_up_profile[0]))) {
		float current_time = force_swing_up_profile[current_index][0];
		float current_torque = force_swing_up_profile[current_index][1];

		// Adjust timing to trigger 0.02 seconds earlier
		float trigger_time = current_time - 0.02f;

		// Prevent first torque from triggering at t=0, should trigger at t=1.98
		if (current_index == 0 && swingup_time < trigger_time) {
			return; // Don't execute until we reach 1.98s
		}

		// If we're in the adjusted time range
		if (swingup_time >= trigger_time) {
			if (current_ramp_called == 0) {
				// Apply friction compensation based on direction
				if (x_dot > 0) {
					current_torque += friction_offsets;
				} else if (x_dot < 0) {
					current_torque -= friction_offsets;
				}

				programed_torque = current_torque;
				programed_ramp = 0.02f;  // Fixed ramp time

				// Call torque ramp function
				MC_ProgramTorqueRampMotor1_F(programed_torque, programed_ramp);

				current_ramp_called = 1;  // Mark ramp as called
				last_ramp_start_time = swingup_time; // Track ramp start
			}
		}

		// Ensure the ramp finishes before incrementing index
		if (current_ramp_called == 1 && (swingup_time - last_ramp_start_time) >= 0.02f) {
			current_index++;
			current_ramp_called = 0; // Allow the next ramp to be called
		}
	}
}

void check_toggle_positions(){
//Read Center Toggle Position
	if(HAL_GPIO_ReadPin(center_toggle_in_GPIO_Port, center_toggle_in_Pin) == GPIO_PIN_SET){
		center_toggle = 1;
	}
	else if(HAL_GPIO_ReadPin(center_toggle_out_GPIO_Port, center_toggle_out_Pin) == GPIO_PIN_SET){
		center_toggle = 3;
	}
	else{
		center_toggle = 2;
	}
//Read Outer Toggle Position
	if(HAL_GPIO_ReadPin(edge_toggle_in_GPIO_Port, edge_toggle_in_Pin) == GPIO_PIN_SET){
		edge_toggle = 3;
	}
	else if(HAL_GPIO_ReadPin(edge_toggle_out_GPIO_Port, edge_toggle_out_Pin) == GPIO_PIN_SET){
		edge_toggle = 1;
	}
	else{
		edge_toggle = 2;
	}

	if(center_toggle == 2){
		white_light_on = true;
	}
	else {
	    white_light_on = false;
	}
}

bool check_motor_temp(){
	  motor_temp = NTC_GetAvTemp_C(&TempSensor_M1);
	  if(motor_temp > 70){
		  motor_temp_high = true;
		  motor_temp_high_flag = true;
	  }
	  else{
		  motor_temp_high = false;
	  }
}

bool check_limit_switch_open(){
//	  if(HAL_GPIO_ReadPin(limit_switch_GPIO_Port, limit_switch_Pin) == GPIO_PIN_RESET){
//		  limit_switch_open = true;
//		  motor_enabled = false;
//		  limit_switch_open_flag = true;
//		  return true;
//	  }
//	  else {
//		  limit_switch_open = false;
//		  return false;
//	  }
}

bool check_soft_limits_breached(){
	  if(x < -1 * soft_limit_length || x > soft_limit_length){
		  soft_limits_breached = true;
		  soft_limits_breached_flag = true;
		  motor_enabled = false;
		  return true;
	  }
	  else {
		  soft_limits_breached = false;
		  return false;
	  }
}

bool check_speed_limit_breached(){
	  if(x_dot < -1* speed_limit || x_dot > speed_limit){
		  speed_limit_breached = true;
		  speed_limit_breached_flag = true;
		  motor_enabled = false;
		  return true;
	  }
	  else{
		  speed_limit_breached = false;
		  return false;
	  }
}

bool check_catch_window_active(){
	  if(theta1 < -1 * catch_window1 || theta1 > catch_window1 || theta2 < -1 * catch_window2 || theta2 > catch_window2 ){
		  catch_window_active = false;
		  motor_enabled = false;
		  yellow_light_on = false;
		  return false;
	  }
	  else{
		  catch_window_active = true;
		  yellow_light_on = true;
		  return true;
	  }
}

const char* GetFaultName(uint8_t fault_code) {
    switch (fault_code) {
        case NO_FAULTS:   return "NO_FAULTS";
        case DURATION:    return "DURATION";
        case OVER_VOLT:   return "OVER_VOLT";
        case UNDER_VOLT:  return "UNDER_VOLT";
        case OVER_TEMP:   return "OVER_TEMP";
        case START_UP:    return "START_UP";
        case SPEED_FDBK:  return "SPEED_FDBK";
        case BREAK_IN:    return "BREAK_IN";
        case SW_ERROR:    return "SW_ERROR";
        default:          return "UNKNOWN_FAULT";
    }
}

bool check_motor_enabled(){
	motor_state = MC_GetSTMStateMotor1();
	if(motor_state == FAULT_OVER){
		fault_code = MC_GetOccurredFaultsMotor1();
		fault_name = GetFaultName(fault_code);
	}

	if(limit_switch_open == false && soft_limits_breached == false && speed_limit_breached == false && catch_window_active == true && center_toggle == 2){
		motor_enabled = true;
		red_light_on = false;
		return true;
	}
	else{
		motor_enabled = false;
		return false;
	}
}

bool check_actively_tracking(){
	if(motor_enabled == true && catch_window_active == true && actively_swinging_up == false){
		return true;
	}
	else{
		return false;
	}
}

void set_indicator_lights(){
//Set Red Light
	if(red_light_on == true){
		HAL_GPIO_WritePin(red_light_GPIO_Port, red_light_Pin, GPIO_PIN_SET);
	}
	else{
		HAL_GPIO_WritePin(red_light_GPIO_Port, red_light_Pin, GPIO_PIN_RESET);
	}
//Set Yellow Light
	if(yellow_light_on == true){
		HAL_GPIO_WritePin(yellow_light_GPIO_Port, yellow_light_Pin, GPIO_PIN_SET);
	}
	else{
		HAL_GPIO_WritePin(yellow_light_GPIO_Port, yellow_light_Pin, GPIO_PIN_RESET);
	}
//Set Green Light
	if(green_light_on == true){
		HAL_GPIO_WritePin(green_light_GPIO_Port, green_light_Pin, GPIO_PIN_SET);
	}
	else{
		HAL_GPIO_WritePin(green_light_GPIO_Port, green_light_Pin, GPIO_PIN_RESET);
	}
//Set White Light
	if(white_light_on == true){
		HAL_GPIO_WritePin(white_light_GPIO_Port, white_light_Pin, GPIO_PIN_SET);
	}
	else{
		HAL_GPIO_WritePin(white_light_GPIO_Port, white_light_Pin, GPIO_PIN_RESET);
	}
}

void drive_motor(){
	  motor_state = MC_GetSTMStateMotor1();
//motor_temp = NTC_GetAvTemp_C(REAL_SENSOR);
	  if(motor_enabled == true){
		  //turn off red light for motor enabled
		  red_light_on = false;

		  //turn on green light for motor enabled
		  green_light_on = true;

		  if(MC_GetSTMStateMotor1() == IDLE){
			  MC_StartMotor1();
		  }

		  current_requested = u * current_constant; //Requested Current in A
		  MC_ProgramTorqueRampMotor1_F(current_requested, 0);
	  }
	  else{
		  MC_StopMotor1();
		  current_requested = 0;
		  MC_ProgramTorqueRampMotor1_F(0, 0);
	  }
}

//moves requested speed into an rpm for speed control signals
float get_rpm(float requested_speed) {
    float set_rpm = (requested_speed * 60) / (2 * 3.1416 * radius);
    return set_rpm;
}

int read_state_machine(){
	//Zero Encoders
	if(state_machine == 2){
		//Stay in state if needed
		if(elapsed_time >3){
			state_machine = 3;
			return state_machine;
		}
		//Return to Hub if anything else
		else{
			state_machine = 2;
		}
		return state_machine;
	}

	//Moving from hub state (no action)
	if(state_machine == 3){
		//Move to Swing Up Control
		if(center_toggle == 1 && edge_toggle == 2){
			state_machine = 4;
		}
		//Move to Actively Tracking Control State
		else if(center_toggle == 2 && edge_toggle == 2 && check_catch_window_active()){
			state_machine = 5;
		}
		//Move to Reset Faults Control State
		else if (edge_toggle == 1){
			state_machine = 6;
		}
		//Move to Zero Encoders State
		else if (edge_toggle == 3) {
			state_machine = 7;
		}
		//Stay in Hub State
		else{
			state_machine = 3;
		}
		return state_machine;
	}

	// In Swing Up State
	if(state_machine == 4){
		//Return if flags are set
		if(soft_limits_breached_flag || speed_limit_breached_flag || limit_switch_open_flag || motor_temp_high_flag){
			state_machine = 3;
		}
		if(soft_limits_breached == true){
			state_machine = 3;
		}

		//Return to Hub for moving control knobs
		if(center_toggle == 2 || center_toggle == 3 || edge_toggle != 2){
			state_machine = 3;
		}
		//Swing Up Successful, transition to active tracking
//			else if(actively_swinging_up == false && catch_window_active){
//				state_machine = 5;
//			}
		//Swing Up Failed, return to hub
//			else if (actively_swinging_up == false && catch_window_active == false) {
//				state_machine = 3;
//			}

		//Stay in Swing Up State
		else{
			state_machine = 4;
		}
		return state_machine;
	}

	//Actively Tracking and praising the Lord
	if(state_machine == 5){
		//Toggles moved back to hub
		if(center_toggle == 1 || edge_toggle != 2){
			state_machine = 3;
		}
		//Arms fall down from active tracking
		if(catch_window_active == false){
			state_machine = 3;
		}
		//Tracking well - praise the Lord and keep going
		else{
			state_machine = 5;
		}
		return state_machine;
	}

	//Zero Encoders
	if(state_machine == 6){
		//Stay in state if needed
		if(edge_toggle == 1){
			state_machine = 6;
		}
		//Return to Hub if anything else
		else{
			state_machine = 3;
		}
		return state_machine;
	}

	//Reset faults and flags
	if(state_machine == 7){
		//Stay in state if needed
		if(edge_toggle == 3){
			state_machine = 7;
		}
		//Return to Hub if anything else
		else{
			state_machine = 3;
		}
		return state_machine;
	}

	else{
		state_machine = 3;
		return state_machine;
	}
	return state_machine;
}

/* USER CODE END 0 */

int main(void)
{

  /* MCU Configuration--------------------------------------------------------*/

  /* Reset of all peripherals, Initializes the Flash interface and the Systick. */
  HAL_Init();

  /* Configure the system clock */
  SystemClock_Config();

  /* Initialize all configured peripherals */
  MX_GPIO_Init();
  MX_DMA_Init();
  MX_ADC1_Init();
  MX_TIM1_Init();
  MX_TIM2_Init();
  MX_USART2_UART_Init();
  MX_MotorControl_Init();
  MX_TIM3_Init();
  MX_TIM4_Init();
  MX_TIM11_Init();
  MX_TIM13_Init();
  MX_TIM14_Init();

  /* Initialize interrupts */
  MX_NVIC_Init();
  /* USER CODE BEGIN 2 */

//Start Interrupt Timers
  HAL_TIM_Base_Start_IT(&htim11); 	//20 Hz
  HAL_TIM_Base_Start_IT(&htim13); 	//100 Hz
  HAL_TIM_Base_Start_IT(&htim14);	//1000 HZ

  NTC_Init(&TempSensor_M1);
//  CircularBuffer theta1_buffer;
//  init_buffer(&theta1_buffer);

  reset_encoder(&theta1_encoder);
  reset_encoder(&theta2_encoder);
  reset_encoder(&x_encoder);

  MC_ProgramTorqueRampMotor1_F(0.00, 1);
  MC_StartMotor1();
  state_machine = 2;

  /* USER CODE END 2 */

  /* Infinite loop */
  while (1)
  {

    /* USER CODE BEGIN 3 */

	  check_toggle_positions();
	  check_motor_temp();
	  check_soft_limits_breached();
	  check_speed_limit_breached();
	  check_catch_window_active();
	  check_motor_enabled();
	  set_indicator_lights();
	  read_state_machine();
	  get_u_value(x, theta1, theta2, x_dot, theta1_dot, theta2_dot);

	  if(state_machine == 2){
		  motor_enabled = true;
	  	  }
	  if(state_machine == 3){
		  MC_StopMotor1();
		  motor_enabled = false;
		  swingup_time = 0;
		  tracking_time = 0;
		  actively_swinging_up = false;
		  actively_tracking = false;
	  }
	  if(state_machine == 4){//Swing Up
		  speed_swing_up();
	  }
	  if(state_machine == 5){//Tracking
		  actively_swinging_up = false;
		  swingup_time = 0;
		  actively_tracking = true;
		  get_u_value(x, theta1, theta2, x_dot, theta1_dot, theta2_dot);
//		  drive_motor();
	  }
	  if(state_machine == 6){//Reset Encoders
		  reset_encoder(&theta1_encoder);
		  reset_encoder(&theta2_encoder);
		  reset_encoder(&x_encoder);
		  x_offset = 0 - x_buffer;
		  theta1_offset = 3.14159 - (theta1_buffer);
		  theta2_offset = 3.14159 - (theta2_buffer);
	  }
	  if(state_machine == 7){//Clear Faults
		  MC_AcknowledgeFaultMotor1();
		  limit_switch_open_flag = false;			//Disable Motor if limit switch is hit
		  motor_temp_high_flag = false;				//Disable Motor if too hot
		  soft_limits_breached_flag = false;		//Disable control if outside of bounds
		  speed_limit_breached_flag = false;		//Disable control if going too fast
		  catch_window_active_flag = false;
	  }

	}
  /* USER CODE END 3 */
}

void SystemClock_Config(void)
{
  RCC_OscInitTypeDef RCC_OscInitStruct = {0};
  RCC_ClkInitTypeDef RCC_ClkInitStruct = {0};

  /** Configure the main internal regulator output voltage
  */
  __HAL_RCC_PWR_CLK_ENABLE();
  __HAL_PWR_VOLTAGESCALING_CONFIG(PWR_REGULATOR_VOLTAGE_SCALE1);

  /** Initializes the RCC Oscillators according to the specified parameters
  * in the RCC_OscInitTypeDef structure.
  */
  RCC_OscInitStruct.OscillatorType = RCC_OSCILLATORTYPE_HSE;
  RCC_OscInitStruct.HSEState = RCC_HSE_ON;
  RCC_OscInitStruct.PLL.PLLState = RCC_PLL_ON;
  RCC_OscInitStruct.PLL.PLLSource = RCC_PLLSOURCE_HSE;
  RCC_OscInitStruct.PLL.PLLM = 4;
  RCC_OscInitStruct.PLL.PLLN = 180;
  RCC_OscInitStruct.PLL.PLLP = RCC_PLLP_DIV2;
  RCC_OscInitStruct.PLL.PLLQ = 2;
  RCC_OscInitStruct.PLL.PLLR = 2;
  if (HAL_RCC_OscConfig(&RCC_OscInitStruct) != HAL_OK)
  {
    Error_Handler();
  }

  /** Activate the Over-Drive mode
  */
  if (HAL_PWREx_EnableOverDrive() != HAL_OK)
  {
    Error_Handler();
  }

  /** Initializes the CPU, AHB and APB buses clocks
  */
  RCC_ClkInitStruct.ClockType = RCC_CLOCKTYPE_HCLK|RCC_CLOCKTYPE_SYSCLK
                              |RCC_CLOCKTYPE_PCLK1|RCC_CLOCKTYPE_PCLK2;
  RCC_ClkInitStruct.SYSCLKSource = RCC_SYSCLKSOURCE_PLLCLK;
  RCC_ClkInitStruct.AHBCLKDivider = RCC_SYSCLK_DIV1;
  RCC_ClkInitStruct.APB1CLKDivider = RCC_HCLK_DIV4;
  RCC_ClkInitStruct.APB2CLKDivider = RCC_HCLK_DIV2;

  if (HAL_RCC_ClockConfig(&RCC_ClkInitStruct, FLASH_LATENCY_5) != HAL_OK)
  {
    Error_Handler();
  }
}

/**
  * @brief NVIC Configuration.
  * @retval None
  */
static void MX_NVIC_Init(void)
{
  /* USART2_IRQn interrupt configuration */
  HAL_NVIC_SetPriority(USART2_IRQn, 3, 1);
  HAL_NVIC_EnableIRQ(USART2_IRQn);
  /* DMA1_Stream5_IRQn interrupt configuration */
  HAL_NVIC_SetPriority(DMA1_Stream5_IRQn, 3, 0);
  HAL_NVIC_EnableIRQ(DMA1_Stream5_IRQn);
  /* ADC_IRQn interrupt configuration */
  HAL_NVIC_SetPriority(ADC_IRQn, 2, 0);
  HAL_NVIC_EnableIRQ(ADC_IRQn);
  /* TIM1_UP_TIM10_IRQn interrupt configuration */
  HAL_NVIC_SetPriority(TIM1_UP_TIM10_IRQn, 0, 0);
  HAL_NVIC_EnableIRQ(TIM1_UP_TIM10_IRQn);
  /* TIM1_BRK_TIM9_IRQn interrupt configuration */
  HAL_NVIC_SetPriority(TIM1_BRK_TIM9_IRQn, 4, 1);
  HAL_NVIC_EnableIRQ(TIM1_BRK_TIM9_IRQn);
  /* TIM2_IRQn interrupt configuration */
  HAL_NVIC_SetPriority(TIM2_IRQn, 3, 0);
  HAL_NVIC_EnableIRQ(TIM2_IRQn);
}

static void MX_ADC1_Init(void)
{

  ADC_InjectionConfTypeDef sConfigInjected = {0};
  ADC_ChannelConfTypeDef sConfig = {0};

  /** Configure the global features of the ADC (Clock, Resolution, Data Alignment and number of conversion)
  */
  hadc1.Instance = ADC1;
  hadc1.Init.ClockPrescaler = ADC_CLOCK_SYNC_PCLK_DIV4;
  hadc1.Init.Resolution = ADC_RESOLUTION_12B;
  hadc1.Init.ScanConvMode = ENABLE;
  hadc1.Init.ContinuousConvMode = DISABLE;
  hadc1.Init.DiscontinuousConvMode = DISABLE;
  hadc1.Init.ExternalTrigConvEdge = ADC_EXTERNALTRIGCONVEDGE_NONE;
  hadc1.Init.ExternalTrigConv = ADC_SOFTWARE_START;
  hadc1.Init.DataAlign = ADC_DATAALIGN_LEFT;
  hadc1.Init.NbrOfConversion = 2;
  hadc1.Init.DMAContinuousRequests = DISABLE;
  hadc1.Init.EOCSelection = ADC_EOC_SINGLE_CONV;
  if (HAL_ADC_Init(&hadc1) != HAL_OK)
  {
    Error_Handler();
  }

  /** Configures for the selected ADC injected channel its corresponding rank in the sequencer and its sample time
  */
  sConfigInjected.InjectedChannel = ADC_CHANNEL_0;
  sConfigInjected.InjectedRank = 1;
  sConfigInjected.InjectedNbrOfConversion = 3;
  sConfigInjected.InjectedSamplingTime = ADC_SAMPLETIME_15CYCLES;
  sConfigInjected.ExternalTrigInjecConvEdge = ADC_EXTERNALTRIGINJECCONVEDGE_RISING;
  sConfigInjected.ExternalTrigInjecConv = ADC_EXTERNALTRIGINJECCONV_T1_CC4;
  sConfigInjected.AutoInjectedConv = DISABLE;
  sConfigInjected.InjectedDiscontinuousConvMode = DISABLE;
  sConfigInjected.InjectedOffset = 0;
  if (HAL_ADCEx_InjectedConfigChannel(&hadc1, &sConfigInjected) != HAL_OK)
  {
    Error_Handler();
  }

  /** Configures for the selected ADC injected channel its corresponding rank in the sequencer and its sample time
  */
  sConfigInjected.InjectedChannel = ADC_CHANNEL_11;
  sConfigInjected.InjectedRank = 2;
  if (HAL_ADCEx_InjectedConfigChannel(&hadc1, &sConfigInjected) != HAL_OK)
  {
    Error_Handler();
  }

  /** Configures for the selected ADC injected channel its corresponding rank in the sequencer and its sample time
  */
  sConfigInjected.InjectedChannel = ADC_CHANNEL_10;
  sConfigInjected.InjectedRank = 3;
  if (HAL_ADCEx_InjectedConfigChannel(&hadc1, &sConfigInjected) != HAL_OK)
  {
    Error_Handler();
  }

  /** Configure for the selected ADC regular channel its corresponding rank in the sequencer and its sample time.
  */
  sConfig.Channel = ADC_CHANNEL_1;
  sConfig.Rank = 1;
  sConfig.SamplingTime = ADC_SAMPLETIME_28CYCLES;
  sConfig.Offset = 0;

  if (HAL_ADC_ConfigChannel(&hadc1, &sConfig) != HAL_OK)
  {
    Error_Handler();
  }

  /** Configure for the selected ADC regular channel its corresponding rank in the sequencer and its sample time.
  */
  sConfig.Channel = ADC_CHANNEL_12;
  sConfig.Rank = 2;

  if (HAL_ADC_ConfigChannel(&hadc1, &sConfig) != HAL_OK)
  {
    Error_Handler();
  }

}

static void MX_TIM1_Init(void)
{

  TIM_MasterConfigTypeDef sMasterConfig = {0};
  TIM_OC_InitTypeDef sConfigOC = {0};
  TIM_BreakDeadTimeConfigTypeDef sBreakDeadTimeConfig = {0};

  htim1.Instance = TIM1;
  htim1.Init.Prescaler = ((TIM_CLOCK_DIVIDER) - 1);
  htim1.Init.CounterMode = TIM_COUNTERMODE_CENTERALIGNED1;
  htim1.Init.Period = ((PWM_PERIOD_CYCLES) / 2);
  htim1.Init.ClockDivision = TIM_CLOCKDIVISION_DIV2;
  htim1.Init.RepetitionCounter = (REP_COUNTER);
  htim1.Init.AutoReloadPreload = TIM_AUTORELOAD_PRELOAD_DISABLE;
  if (HAL_TIM_PWM_Init(&htim1) != HAL_OK)
  {
    Error_Handler();
  }
  sMasterConfig.MasterOutputTrigger = TIM_TRGO_RESET;
  sMasterConfig.MasterSlaveMode = TIM_MASTERSLAVEMODE_DISABLE;
  if (HAL_TIMEx_MasterConfigSynchronization(&htim1, &sMasterConfig) != HAL_OK)
  {
    Error_Handler();
  }
  sConfigOC.OCMode = TIM_OCMODE_PWM1;
  sConfigOC.Pulse = ((PWM_PERIOD_CYCLES) / 4);
  sConfigOC.OCPolarity = TIM_OCPOLARITY_HIGH;
  sConfigOC.OCNPolarity = TIM_OCNPOLARITY_LOW;
  sConfigOC.OCFastMode = TIM_OCFAST_DISABLE;
  sConfigOC.OCIdleState = TIM_OCIDLESTATE_RESET;
  sConfigOC.OCNIdleState = TIM_OCNIDLESTATE_SET;
  if (HAL_TIM_PWM_ConfigChannel(&htim1, &sConfigOC, TIM_CHANNEL_1) != HAL_OK)
  {
    Error_Handler();
  }
  if (HAL_TIM_PWM_ConfigChannel(&htim1, &sConfigOC, TIM_CHANNEL_2) != HAL_OK)
  {
    Error_Handler();
  }
  if (HAL_TIM_PWM_ConfigChannel(&htim1, &sConfigOC, TIM_CHANNEL_3) != HAL_OK)
  {
    Error_Handler();
  }
  sConfigOC.OCMode = TIM_OCMODE_PWM2;
  sConfigOC.Pulse = (((PWM_PERIOD_CYCLES) / 2) - (HTMIN));
  sConfigOC.OCNIdleState = TIM_OCNIDLESTATE_RESET;
  if (HAL_TIM_PWM_ConfigChannel(&htim1, &sConfigOC, TIM_CHANNEL_4) != HAL_OK)
  {
    Error_Handler();
  }
  sBreakDeadTimeConfig.OffStateRunMode = TIM_OSSR_ENABLE;
  sBreakDeadTimeConfig.OffStateIDLEMode = TIM_OSSI_ENABLE;
  sBreakDeadTimeConfig.LockLevel = TIM_LOCKLEVEL_OFF;
  sBreakDeadTimeConfig.DeadTime = ((DEAD_TIME_COUNTS) / 2);
  sBreakDeadTimeConfig.BreakState = TIM_BREAK_ENABLE;
  sBreakDeadTimeConfig.BreakPolarity = TIM_BREAKPOLARITY_LOW;
  sBreakDeadTimeConfig.AutomaticOutput = TIM_AUTOMATICOUTPUT_DISABLE;
  if (HAL_TIMEx_ConfigBreakDeadTime(&htim1, &sBreakDeadTimeConfig) != HAL_OK)
  {
    Error_Handler();
  }
  HAL_TIM_MspPostInit(&htim1);

}

static void MX_TIM2_Init(void)
{

  TIM_Encoder_InitTypeDef sConfig = {0};
  TIM_MasterConfigTypeDef sMasterConfig = {0};

  htim2.Instance = TIM2;
  htim2.Init.Prescaler = 0;
  htim2.Init.CounterMode = TIM_COUNTERMODE_UP;
  htim2.Init.Period = M1_PULSE_NBR;
  htim2.Init.ClockDivision = TIM_CLOCKDIVISION_DIV1;
  htim2.Init.AutoReloadPreload = TIM_AUTORELOAD_PRELOAD_DISABLE;
  sConfig.EncoderMode = TIM_ENCODERMODE_TI12;
  sConfig.IC1Polarity = TIM_ICPOLARITY_RISING;
  sConfig.IC1Selection = TIM_ICSELECTION_DIRECTTI;
  sConfig.IC1Prescaler = TIM_ICPSC_DIV1;
  sConfig.IC1Filter = M1_ENC_IC_FILTER;
  sConfig.IC2Polarity = TIM_ICPOLARITY_RISING;
  sConfig.IC2Selection = TIM_ICSELECTION_DIRECTTI;
  sConfig.IC2Prescaler = TIM_ICPSC_DIV1;
  sConfig.IC2Filter = M1_ENC_IC_FILTER;
  if (HAL_TIM_Encoder_Init(&htim2, &sConfig) != HAL_OK)
  {
    Error_Handler();
  }
  sMasterConfig.MasterOutputTrigger = TIM_TRGO_RESET;
  sMasterConfig.MasterSlaveMode = TIM_MASTERSLAVEMODE_DISABLE;
  if (HAL_TIMEx_MasterConfigSynchronization(&htim2, &sMasterConfig) != HAL_OK)
  {
    Error_Handler();
  }
  /* USER CODE BEGIN TIM2_Init 2 */
  HAL_TIM_Encoder_Start(&htim2, TIM_CHANNEL_ALL); //Start x encoder
  /* USER CODE END TIM2_Init 2 */

}

static void MX_TIM3_Init(void)
{

  TIM_Encoder_InitTypeDef sConfig = {0};
  TIM_MasterConfigTypeDef sMasterConfig = {0};

  htim3.Instance = TIM3;
  htim3.Init.Prescaler = 0;
  htim3.Init.CounterMode = TIM_COUNTERMODE_UP;
  htim3.Init.Period = 65535;
  htim3.Init.ClockDivision = TIM_CLOCKDIVISION_DIV1;
  htim3.Init.AutoReloadPreload = TIM_AUTORELOAD_PRELOAD_ENABLE;
  sConfig.EncoderMode = TIM_ENCODERMODE_TI12;
  sConfig.IC1Polarity = TIM_ICPOLARITY_RISING;
  sConfig.IC1Selection = TIM_ICSELECTION_DIRECTTI;
  sConfig.IC1Prescaler = TIM_ICPSC_DIV1;
  sConfig.IC1Filter = 0;
  sConfig.IC2Polarity = TIM_ICPOLARITY_RISING;
  sConfig.IC2Selection = TIM_ICSELECTION_DIRECTTI;
  sConfig.IC2Prescaler = TIM_ICPSC_DIV1;
  sConfig.IC2Filter = 0;
  if (HAL_TIM_Encoder_Init(&htim3, &sConfig) != HAL_OK)
  {
    Error_Handler();
  }
  sMasterConfig.MasterOutputTrigger = TIM_TRGO_RESET;
  sMasterConfig.MasterSlaveMode = TIM_MASTERSLAVEMODE_DISABLE;
  if (HAL_TIMEx_MasterConfigSynchronization(&htim3, &sMasterConfig) != HAL_OK)
  {
    Error_Handler();
  }
  /* USER CODE BEGIN TIM3_Init 2 */
  HAL_TIM_Encoder_Start(&htim3, TIM_CHANNEL_ALL); //Start theta1 encoder
  /* USER CODE END TIM3_Init 2 */

}

static void MX_TIM4_Init(void)
{

  TIM_Encoder_InitTypeDef sConfig = {0};
  TIM_MasterConfigTypeDef sMasterConfig = {0};

  htim4.Instance = TIM4;
  htim4.Init.Prescaler = 0;
  htim4.Init.CounterMode = TIM_COUNTERMODE_UP;
  htim4.Init.Period = 65535;
  htim4.Init.ClockDivision = TIM_CLOCKDIVISION_DIV1;
  htim4.Init.AutoReloadPreload = TIM_AUTORELOAD_PRELOAD_ENABLE;
  sConfig.EncoderMode = TIM_ENCODERMODE_TI12;
  sConfig.IC1Polarity = TIM_ICPOLARITY_RISING;
  sConfig.IC1Selection = TIM_ICSELECTION_DIRECTTI;
  sConfig.IC1Prescaler = TIM_ICPSC_DIV1;
  sConfig.IC1Filter = 0;
  sConfig.IC2Polarity = TIM_ICPOLARITY_RISING;
  sConfig.IC2Selection = TIM_ICSELECTION_DIRECTTI;
  sConfig.IC2Prescaler = TIM_ICPSC_DIV1;
  sConfig.IC2Filter = 0;
  if (HAL_TIM_Encoder_Init(&htim4, &sConfig) != HAL_OK)
  {
    Error_Handler();
  }
  sMasterConfig.MasterOutputTrigger = TIM_TRGO_RESET;
  sMasterConfig.MasterSlaveMode = TIM_MASTERSLAVEMODE_DISABLE;
  if (HAL_TIMEx_MasterConfigSynchronization(&htim4, &sMasterConfig) != HAL_OK)
  {
    Error_Handler();
  }
  /* USER CODE BEGIN TIM4_Init 2 */
  HAL_TIM_Encoder_Start(&htim4, TIM_CHANNEL_ALL); //Start theta2 encoder
  /* USER CODE END TIM4_Init 2 */

}

static void MX_TIM11_Init(void)
{

  htim11.Instance = TIM11;
  htim11.Init.Prescaler = 180-1;
  htim11.Init.CounterMode = TIM_COUNTERMODE_UP;
  htim11.Init.Period = 20000-1;
  htim11.Init.ClockDivision = TIM_CLOCKDIVISION_DIV1;
  htim11.Init.AutoReloadPreload = TIM_AUTORELOAD_PRELOAD_ENABLE;
  if (HAL_TIM_Base_Init(&htim11) != HAL_OK)
  {
    Error_Handler();
  }

}

static void MX_TIM13_Init(void)
{

  htim13.Instance = TIM13;
  htim13.Init.Prescaler = 90-1;
  htim13.Init.CounterMode = TIM_COUNTERMODE_UP;
  htim13.Init.Period = 10000-1;
  htim13.Init.ClockDivision = TIM_CLOCKDIVISION_DIV1;
  htim13.Init.AutoReloadPreload = TIM_AUTORELOAD_PRELOAD_DISABLE;
  if (HAL_TIM_Base_Init(&htim13) != HAL_OK)
  {
    Error_Handler();
  }

}

static void MX_TIM14_Init(void)
{

  htim14.Instance = TIM14;
  htim14.Init.Prescaler = 90-1;
  htim14.Init.CounterMode = TIM_COUNTERMODE_UP;
  htim14.Init.Period = 1000-1;
  htim14.Init.ClockDivision = TIM_CLOCKDIVISION_DIV1;
  htim14.Init.AutoReloadPreload = TIM_AUTORELOAD_PRELOAD_DISABLE;
  if (HAL_TIM_Base_Init(&htim14) != HAL_OK)
  {
    Error_Handler();
  }

}

static void MX_USART2_UART_Init(void)
{

  huart2.Instance = USART2;
  huart2.Init.BaudRate = 115200;
  huart2.Init.WordLength = UART_WORDLENGTH_8B;
  huart2.Init.StopBits = UART_STOPBITS_1;
  huart2.Init.Parity = UART_PARITY_NONE;
  huart2.Init.Mode = UART_MODE_TX_RX;
  huart2.Init.HwFlowCtl = UART_HWCONTROL_NONE;
  huart2.Init.OverSampling = UART_OVERSAMPLING_16;
  if (HAL_UART_Init(&huart2) != HAL_OK)
  {
    Error_Handler();
  }

}

static void MX_DMA_Init(void)
{

  /* DMA controller clock enable */
  __HAL_RCC_DMA1_CLK_ENABLE();

}

static void MX_GPIO_Init(void)
{
  GPIO_InitTypeDef GPIO_InitStruct = {0};

  /* GPIO Ports Clock Enable */
  __HAL_RCC_GPIOH_CLK_ENABLE();
  __HAL_RCC_GPIOC_CLK_ENABLE();
  __HAL_RCC_GPIOA_CLK_ENABLE();
  __HAL_RCC_GPIOB_CLK_ENABLE();

  /*Configure GPIO pin Output Level */
  HAL_GPIO_WritePin(GPIOC, red_light_Pin|white_light_Pin|green_light_Pin, GPIO_PIN_SET);

  /*Configure GPIO pin Output Level */
  HAL_GPIO_WritePin(yellow_light_GPIO_Port, yellow_light_Pin, GPIO_PIN_SET);

  /*Configure GPIO pins : red_light_Pin white_light_Pin green_light_Pin */
  GPIO_InitStruct.Pin = red_light_Pin|white_light_Pin|green_light_Pin;
  GPIO_InitStruct.Mode = GPIO_MODE_OUTPUT_PP;
  GPIO_InitStruct.Pull = GPIO_NOPULL;
  GPIO_InitStruct.Speed = GPIO_SPEED_FREQ_LOW;
  HAL_GPIO_Init(GPIOC, &GPIO_InitStruct);

  /*Configure GPIO pins : edge_toggle_in_Pin edge_toggle_out_Pin limit_switch_Pin */
  GPIO_InitStruct.Pin = edge_toggle_in_Pin|edge_toggle_out_Pin|limit_switch_Pin;
  GPIO_InitStruct.Mode = GPIO_MODE_INPUT;
  GPIO_InitStruct.Pull = GPIO_PULLDOWN;
  HAL_GPIO_Init(GPIOC, &GPIO_InitStruct);

  /*Configure GPIO pins : center_toggle_out_Pin center_toggle_in_Pin */
  GPIO_InitStruct.Pin = center_toggle_out_Pin|center_toggle_in_Pin;
  GPIO_InitStruct.Mode = GPIO_MODE_INPUT;
  GPIO_InitStruct.Pull = GPIO_PULLDOWN;
  HAL_GPIO_Init(GPIOB, &GPIO_InitStruct);

  /*Configure GPIO pin : yellow_light_Pin */
  GPIO_InitStruct.Pin = yellow_light_Pin;
  GPIO_InitStruct.Mode = GPIO_MODE_OUTPUT_PP;
  GPIO_InitStruct.Pull = GPIO_NOPULL;
  GPIO_InitStruct.Speed = GPIO_SPEED_FREQ_LOW;
  HAL_GPIO_Init(yellow_light_GPIO_Port, &GPIO_InitStruct);

}

void Error_Handler(void)
{
  __disable_irq();
  while (1)
  {
  }
}
